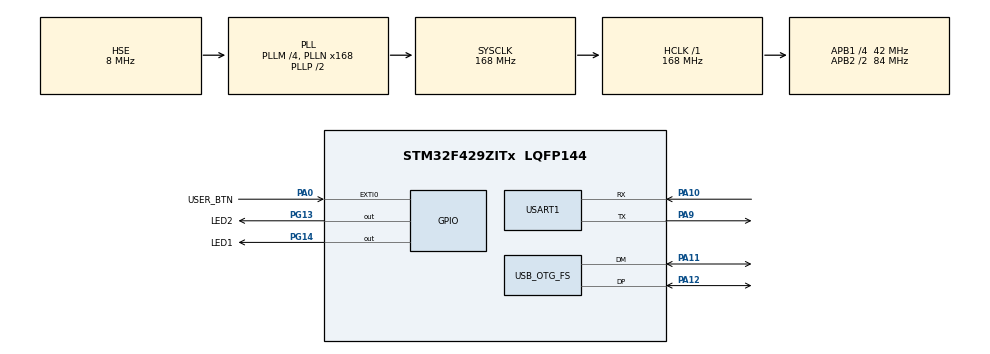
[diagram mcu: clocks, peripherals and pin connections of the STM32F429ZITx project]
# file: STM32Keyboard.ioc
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Mcu.Family=STM32F4
USB_DEVICE.CLASS_NAME_FS=CUSTOM_HID
RCC.CortexFreq_Value=168000000
USB_DEVICE.CUSTOM_HID_FS_BINTERVAL=0x0A
PA10.Mode=Asynchronous
USB_DEVICE.VirtualModeFS=Custom_Hid_FS
VP_USB_DEVICE_VS_USB_DEVICE_CUSTOM_HID_FS.Mode=CUSTOM_HID_FS
PA11.Mode=Device_Only
PA0/WKUP.Signal=GPXTI0
RCC.APB1CLKDivider=RCC_HCLK_DIV4
PG13.Signal=GPIO_Output
PG13.GPIO_Label=LED2
RCC.SYSCLKSource=RCC_SYSCLKSOURCE_PLLCLK
ProjectManager.StackSize=0x400
PA13.Signal=SYS_JTMS-SWDIO
PA9.Mode=Asynchronous
PA12.Signal=USB_OTG_FS_DP
ProjectManager.TargetToolchain=STM32CubeIDE
PH0/OSC_IN.Mode=HSE-External-Oscillator
RCC.HCLKFreq_Value=168000000
RCC.APB2TimFreq_Value=168000000
PA9.Signal=USART1_TX
PH1/OSC_OUT.Signal=RCC_OSC_OUT
RCC.LSE_VALUE=32768
RCC.AHBFreq_Value=168000000
USB_DEVICE.PRODUCT_STRING_CUSTOMHID_FS=TheDucky
PG14.Signal=GPIO_Output
RCC.HSE_VALUE=8000000
board=STM32F429I-DISC1
RCC.VCOOutputFreq_Value=336000000
PH0/OSC_IN.Signal=RCC_OSC_IN
RCC.APB2Freq_Value=84000000
PA14.Mode=Serial_Wire
PA0/WKUP.GPIO_Label=USER_BTN
PA13.Mode=Serial_Wire
PG14.GPIO_Label=LED1
PH1/OSC_OUT.Mode=HSE-External-Oscillator
Mcu.Name=STM32F429ZITx
RCC.48MHZClocksFreq_Value=48000000
NVIC.EXTI0_IRQn=true\:0\:0\:false\:false\:true\:true\:true
RCC.SYSCLKFreq_VALUE=168000000
Mcu.Package=LQFP144
PA12.Mode=Device_Only
USB_DEVICE.VirtualMode-CUSTOM_HID_FS=CustomHid
USB_DEVICE.USBD_CUSTOM_HID_REPORT_DESC_SIZE-CUSTOM_HID_FS=63
NVIC.OTG_FS_IRQn=true\:0\:0\:false\:false\:true\:false\:true
USART1.VirtualMode=VM_ASYNC
PA11.Signal=USB_OTG_FS_DM
PA10.Signal=USART1_RX
PA14.Signal=SYS_JTCK-SWCLK
USB_OTG_FS.VirtualMode=Device_Only
ProjectManager.HeapSize=0x200
USB_DEVICE.USBD_CUSTOMHID_OUTREPORT_BUF_SIZE-CUSTOM_HID_FS=8
RCC.HSI_VALUE=16000000
RCC.PLLQ=7
NVIC.PriorityGroup=NVIC_PRIORITYGROUP_0
RCC.APB2CLKDivider=RCC_HCLK_DIV2
RCC.PLLM=4
RCC.PLLN=168
RCC.APB1TimFreq_Value=84000000
NVIC.USART1_IRQn=true\:0\:0\:false\:false\:true\:true\:true
RCC.APB1Freq_Value=42000000

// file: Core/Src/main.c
/* USER CODE BEGIN Header */
/**
  ******************************************************************************
  * @file           : main.c
  * @brief          : Main program body
  ******************************************************************************
  * @attention
  *
  * <h2><center>&copy; Copyright (c) 2021 STMicroelectronics.
  * All rights reserved.</center></h2>
  *
  * This software component is licensed by ST under BSD 3-Clause license,
  * the "License"; You may not use this file except in compliance with the
  * License. You may obtain a copy of the License at:
  *                        opensource.org/licenses/BSD-3-Clause
  *
  ******************************************************************************
  */
/* USER CODE END Header */
#include "main.h"
#include "usb_device.h"

/* USER CODE BEGIN Includes */
#include "Keyboard.h"
/* USER CODE END Includes */

UART_HandleTypeDef huart1;

void SystemClock_Config(void);
static void MX_GPIO_Init(void);
static void MX_USART1_UART_Init(void);

int main(void)
{

  /* MCU Configuration--------------------------------------------------------*/

  /* Reset of all peripherals, Initializes the Flash interface and the Systick. */
  HAL_Init();

  /* Configure the system clock */
  SystemClock_Config();

  /* Initialize all configured peripherals */
  MX_GPIO_Init();
  MX_USART1_UART_Init();
  MX_USB_DEVICE_Init();
  /* USER CODE BEGIN 2 */
  Keyboard_init();
  /* USER CODE END 2 */

  /* Infinite loop */
  while (1)
  {

    /* USER CODE BEGIN 3 */
	  HAL_Delay(1000);
	  Keyboard_write("Hello World!!\n");
	  HAL_Delay(1000);
	  Keyboard_write("Good bye Cruel World!!\n");

  }
  /* USER CODE END 3 */
}

void SystemClock_Config(void)
{
  RCC_OscInitTypeDef RCC_OscInitStruct = {0};
  RCC_ClkInitTypeDef RCC_ClkInitStruct = {0};

  /** Configure the main internal regulator output voltage
  */
  __HAL_RCC_PWR_CLK_ENABLE();
  __HAL_PWR_VOLTAGESCALING_CONFIG(PWR_REGULATOR_VOLTAGE_SCALE1);
  /** Initializes the RCC Oscillators according to the specified parameters
  * in the RCC_OscInitTypeDef structure.
  */
  RCC_OscInitStruct.OscillatorType = RCC_OSCILLATORTYPE_HSE;
  RCC_OscInitStruct.HSEState = RCC_HSE_ON;
  RCC_OscInitStruct.PLL.PLLState = RCC_PLL_ON;
  RCC_OscInitStruct.PLL.PLLSource = RCC_PLLSOURCE_HSE;
  RCC_OscInitStruct.PLL.PLLM = 4;
  RCC_OscInitStruct.PLL.PLLN = 168;
  RCC_OscInitStruct.PLL.PLLP = RCC_PLLP_DIV2;
  RCC_OscInitStruct.PLL.PLLQ = 7;
  if (HAL_RCC_OscConfig(&RCC_OscInitStruct) != HAL_OK)
  {
    Error_Handler();
  }
  /** Initializes the CPU, AHB and APB buses clocks
  */
  RCC_ClkInitStruct.ClockType = RCC_CLOCKTYPE_HCLK|RCC_CLOCKTYPE_SYSCLK
                              |RCC_CLOCKTYPE_PCLK1|RCC_CLOCKTYPE_PCLK2;
  RCC_ClkInitStruct.SYSCLKSource = RCC_SYSCLKSOURCE_PLLCLK;
  RCC_ClkInitStruct.AHBCLKDivider = RCC_SYSCLK_DIV1;
  RCC_ClkInitStruct.APB1CLKDivider = RCC_HCLK_DIV4;
  RCC_ClkInitStruct.APB2CLKDivider = RCC_HCLK_DIV2;

  if (HAL_RCC_ClockConfig(&RCC_ClkInitStruct, FLASH_LATENCY_5) != HAL_OK)
  {
    Error_Handler();
  }
}

static void MX_USART1_UART_Init(void)
{

  huart1.Instance = USART1;
  huart1.Init.BaudRate = 115200;
  huart1.Init.WordLength = UART_WORDLENGTH_8B;
  huart1.Init.StopBits = UART_STOPBITS_1;
  huart1.Init.Parity = UART_PARITY_NONE;
  huart1.Init.Mode = UART_MODE_TX_RX;
  huart1.Init.HwFlowCtl = UART_HWCONTROL_NONE;
  huart1.Init.OverSampling = UART_OVERSAMPLING_16;
  if (HAL_UART_Init(&huart1) != HAL_OK)
  {
    Error_Handler();
  }

}

static void MX_GPIO_Init(void)
{
  GPIO_InitTypeDef GPIO_InitStruct = {0};

  /* GPIO Ports Clock Enable */
  __HAL_RCC_GPIOH_CLK_ENABLE();
  __HAL_RCC_GPIOA_CLK_ENABLE();
  __HAL_RCC_GPIOG_CLK_ENABLE();

  /*Configure GPIO pin Output Level */
  HAL_GPIO_WritePin(GPIOG, LED2_Pin|LED1_Pin, GPIO_PIN_RESET);

  /*Configure GPIO pin : USER_BTN_Pin */
  GPIO_InitStruct.Pin = USER_BTN_Pin;
  GPIO_InitStruct.Mode = GPIO_MODE_IT_RISING;
  GPIO_InitStruct.Pull = GPIO_NOPULL;
  HAL_GPIO_Init(USER_BTN_GPIO_Port, &GPIO_InitStruct);

  /*Configure GPIO pins : LED2_Pin LED1_Pin */
  GPIO_InitStruct.Pin = LED2_Pin|LED1_Pin;
  GPIO_InitStruct.Mode = GPIO_MODE_OUTPUT_PP;
  GPIO_InitStruct.Pull = GPIO_NOPULL;
  GPIO_InitStruct.Speed = GPIO_SPEED_FREQ_LOW;
  HAL_GPIO_Init(GPIOG, &GPIO_InitStruct);

  /* EXTI interrupt init*/
  HAL_NVIC_SetPriority(EXTI0_IRQn, 0, 0);
  HAL_NVIC_EnableIRQ(EXTI0_IRQn);

}

void Error_Handler(void)
{
}

/************************ (C) COPYRIGHT STMicroelectronics *****END OF FILE****/
